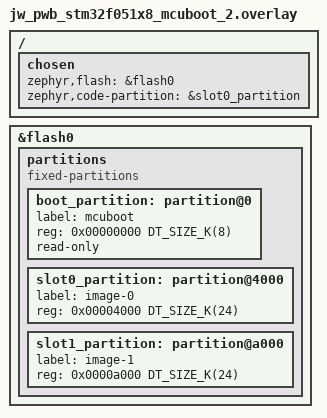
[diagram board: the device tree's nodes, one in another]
/{
	chosen {
		zephyr,flash = &flash0;
		zephyr,code-partition = &slot0_partition;
	};
}

&flash0 {
	partitions {
		compatible = "fixed-partitions";
		#address-cells = <1>;
		#size-cells = <1>;

		boot_partition: partition@0 {
			label = "mcuboot";
			reg = <0x00000000 DT_SIZE_K(8)>;
			read-only;
		};

		/*
		 * The flash starting at offset 0x2000 and ending at
		 * offset 0x3999 is reserved for use by the application.
		 */

		slot0_partition: partition@4000 {
			label = "image-0";
			reg = <0x00004000 DT_SIZE_K(24)>;
		};
		slot1_partition: partition@a000 {
			label = "image-1";
			reg = <0x0000a000 DT_SIZE_K(24)>;
		};
	};
};
